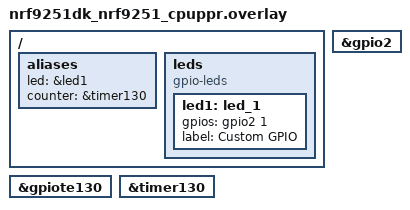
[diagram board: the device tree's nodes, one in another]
/*
 * Copyright (c) 2026 Nordic Semiconductor ASA
 *
 * SPDX-License-Identifier: LicenseRef-Nordic-5-Clause
 */

#include <zephyr/dt-bindings/gpio/nordic-nrf-gpio.h>

/ {
	aliases {
		led = &led1;
		counter = &timer130;
	};

	leds {
		compatible = "gpio-leds";

		/* Move to other GPIO. */
		led1: led_1 {
			gpios = <&gpio2 1 GPIO_ACTIVE_HIGH>;
			label = "Custom GPIO";
		};
	};
};

&gpio2 {
	status = "okay";
};

&gpiote130 {
	status = "okay";
};

&timer130 {
	status = "okay";
};
